# GD32L235x register map
File version: 1.0
CPU: CM23 r1p0, little endian, no MPU, no FPU, 2 interrupt priority bits
Registers are 32-bit, read-write, reset 0x0 unless marked. A register's access mark holds for its fields unless they carry their own. Offsets are from the block's base; [hi:lo] are bit positions; {n}, {i} and the like mark numbered series.

## DMAMUX — DMAMUX controller
Base 0x40020800
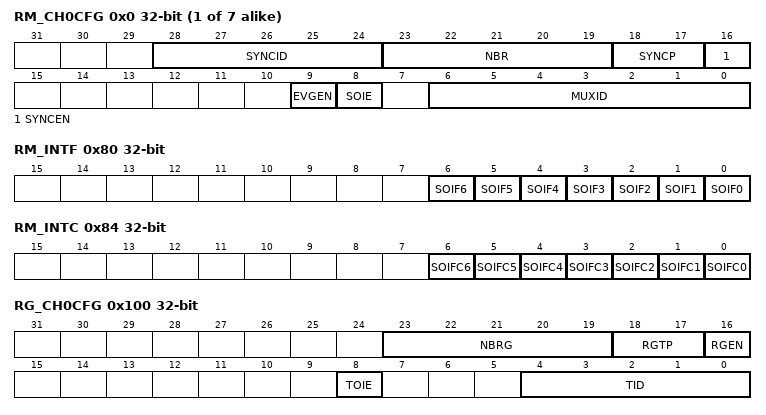
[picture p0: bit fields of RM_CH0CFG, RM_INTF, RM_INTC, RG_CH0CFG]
{0x0+4i} RM_CH{i}CFG (i=0..6) — Request multiplexer channel x configuration register
  [28:24] SYNCID — Synchronization input identification
  [23:19] NBR — Number of DMA requests to forward
  [18:17] SYNCP — Synchronization input polarity
  [16] SYNCEN — Synchronization enable
  [9] EVGEN — Event generation enable
  [8] SOIE — Synchronization overrun interrupt enable
  [6:0] MUXID — Multiplexer input identification
0x80 RM_INTF ro — Request multiplexer channel interrupt flag register
  [n] SOIF{n} (n=0..6) — Synchronization overrun event flag of request multiplexer channel {n}
0x84 RM_INTC wo — Request multiplexer channel interrupt flag clear register
  [n] SOIFC{n} (n=0..6) — Clear bit for synchronization overrun event flag of request multiplexer channel {n}
0x100 RG_CH0CFG — Request generator channel x configuration register
  [23:19] NBRG — Number of DMA requests to be generated
  [18:17] RGTP — DMA request generator trigger polarity
  [16] RGEN — DMAMUX request generator channel x enable
  [8] TOIE — Trigger overrun interrupt enable
  [4:0] TID — Trigger input identification
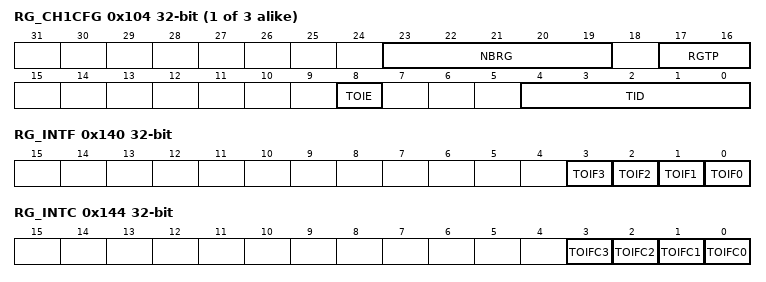
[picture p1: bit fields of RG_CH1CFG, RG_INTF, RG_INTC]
{0x100+4i} RG_CH{i}CFG (i=1..3) — Request generator channel {i} configuration register
  [23:19] NBRG — Number of DMA requests to be generated
  [17:16] RGTP — DMA request generator trigger polarity
  [8] TOIE — Trigger overrun interrupt enable
  [4:0] TID — Trigger input identification
0x140 RG_INTF ro — Request generator interrupt flag register
  [n] TOIF{n} (n=0..3) — Trigger overrun event flag of request generator channel {n}
0x144 RG_INTC ro — Rquest generator interrupt flag clear register
  [n] TOIFC{n} (n=0..3) — Clear bit for trigger overrun event flag of request generator channel {n}

## EXTI — External interrupt/event controller
Base 0x40010400
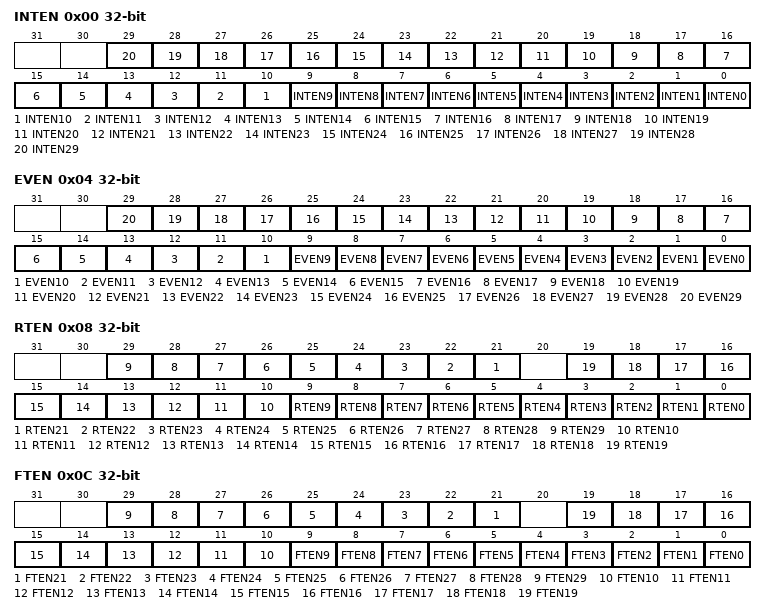
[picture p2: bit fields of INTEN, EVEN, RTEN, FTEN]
0x00 INTEN — Interrupt enable register (EXTI_INTEN)
  [n] INTEN{n} (n=0..29) — Enable Interrupt on line {n}
0x04 EVEN — Event enable register (EXTI_EVEN)
  [n] EVEN{n} (n=0..29) — Enable Event on line {n}
0x08 RTEN — Rising Edge Trigger Enable register (EXTI_RTEN)
  [n] RTEN{n} (n=21..29) — Rising trigger event configuration of line {n}
  [n] RTEN{n} (n=0..19) — Rising trigger event configuration of line {n}
0x0C FTEN — Falling Egde Trigger Enable register (EXTI_FTEN)
  [n] FTEN{n} (n=21..29) — Falling trigger event configuration of line {n}
  [n] FTEN{n} (n=0..19) — Falling trigger event configuration of line {n}
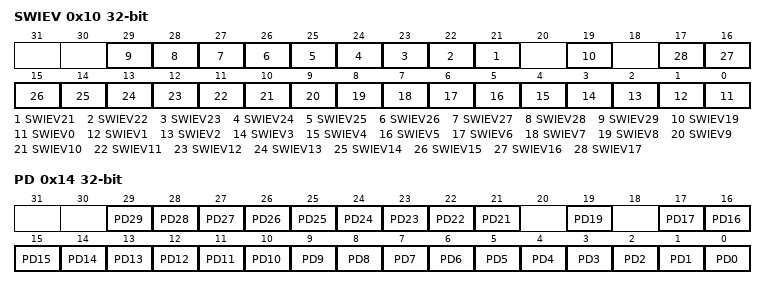
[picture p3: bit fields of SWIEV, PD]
0x10 SWIEV — Software interrupt event register (EXTI_SWIEV)
  [n] SWIEV{n} (n=21..29) — Software Interrupt on line {n}
  [19] SWIEV19 — Software Interrupt on line 19
  [n] SWIEV{n} (n=0..17) — Software Interrupt on line {n}
0x14 PD — Pending register (EXTI_PD)
  [n] PD{n} (n=21..29) — Pending bit {n}
  [19] PD19 — Pending bit 19
  [n] PD{n} (n=0..17) — Pending bit {n}

## FMC
Base 0x40022000
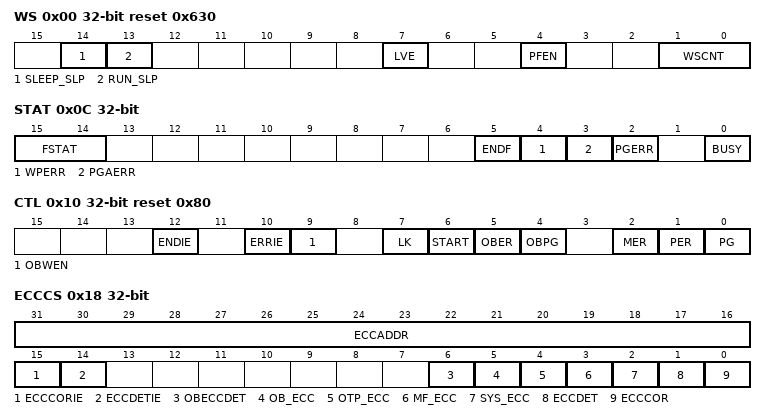
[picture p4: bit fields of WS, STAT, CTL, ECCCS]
0x00 WS reset 0x630 — wait state register
  [14] SLEEP_SLP — Flash enter sleep mode or power-down mode
  [13] RUN_SLP — Flash enter sleep/power-down mode
  [7] LVE — Low power enable
  [4] PFEN — Pre-fetch enable
  [1:0] WSCNT — wait state counter register
0x04 KEY wo — Unlock key register
  [31:0] KEY — FMC_CTL unlock register
0x08 OBKEY wo — Option byte unlock key register
  [31:0] OBKEY — FMC_ CTL option bytes operation unlock register
0x0C STAT access per field — Status register
  [15:14] FSTAT rw — Flash status
  [5] ENDF rw — End of operation flag bit
  [4] WPERR rw — Erase/Program protection error flag bit
  [3] PGAERR rw — Program alignment error flag bit
  [2] PGERR rw — Program error flag bit
  [0] BUSY ro — The flash is busy bit
0x10 CTL reset 0x80 — Control register
  [12] ENDIE — End of operation interrupt enable bit
  [10] ERRIE — Error interrupt enable bit
  [9] OBWEN — Option byte erase/program enable bit
  [7] LK — FMC_CTL lock bit
  [6] START — Send erase command to FMC bit
  [5] OBER — Option bytes erase command bit
  [4] OBPG — Option bytes program command bit
  [2] MER — Main flash mass erase for bank0 command bit
  [1] PER — Main flash page erase for bank0 command bit
  [0] PG — Main flash program for bank0 command bit
0x14 ADDR — Address register
  [31:0] ADDR — Flash erase/program command address bits
0x18 ECCCS access per field — ECC control and status register
  [31:16] ECCADDR ro — The offset address of double word where an ECC error is detected
  [15] ECCCORIE rw — One bit error correct interrupt enable
  [14] ECCDETIE rw — Two bits errors detect interrupt enable
  [6] OBECCDET rw — Option bytes two bits errors detect flag
  [5] OB_ECC rw — ECC bit error is detected in reading option bytes
  [4] OTP_ECC rw — ECC bit error is detected in OTP
  [3] MF_ECC rw — ECC bit error is detected in main Flash
  [2] SYS_ECC rw — ECC bit error is detected in system memory
  [1] ECCDET rw — Two bit errors detect flag
  [0] ECCCOR rw — One bit error detected and correct flag
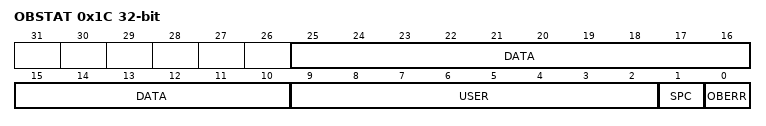
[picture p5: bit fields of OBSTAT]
0x1C OBSTAT ro — Option byte control register
  [25:10] DATA — Store DATA[15:0] of option bytes block after system reset
  [9:2] USER — Store USER of option bytes block after system reset
  [1] SPC — Option bytes security protection code
  [0] OBERR — Option bytes read error bit
0x20 WP ro — Erase/Program Protection register
  [31:0] WP — Store WP[15:0] of option bytes block after system reset
0x24 SLP_KEY wo — Unlock flash sleep/power down mode key register
  [31:0] SLPKEY — RUN_SLP unlock register
0x100 PID0 ro — Product ID register
  [31:0] PID — Product reserved ID code register
